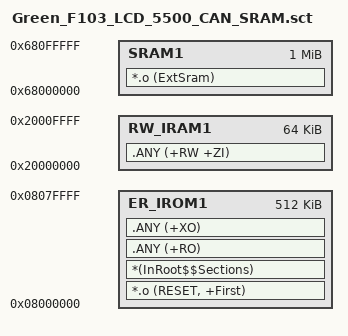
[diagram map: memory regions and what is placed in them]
; *************************************************************
; *** Scatter-Loading Description File generated by uVision ***
; *************************************************************

LR_IROM1 0x08000000 0x00080000  {    ; load region size_region
  ER_IROM1 0x08000000 0x00080000  {  ; load address = execution address
   *.o (RESET, +First)
   *(InRoot$$Sections)
   .ANY (+RO)
   .ANY (+XO)
  }
  RW_IRAM1 0x20000000 0x00010000  {  ; RW data
   .ANY (+RW +ZI)
  }
}

LR_EROM1 0x68000000 0x00100000  {   
  SRAM1 0x68000000 0x00100000  {  ; RW data
   *.o (ExtSram)
  }
}
